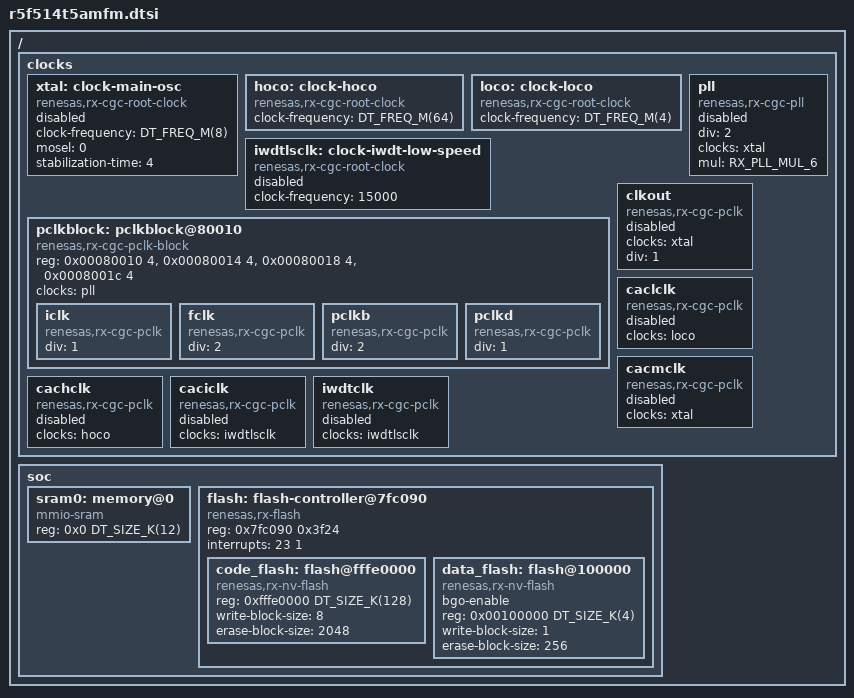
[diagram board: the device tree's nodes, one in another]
/*
 * Copyright (c) 2026 Renesas Electronics Corporation
 *
 * SPDX-License-Identifier: Apache-2.0
 */
#include <rx/renesas/rx14t-common.dtsi>
#include <freq.h>
#include <zephyr/dt-bindings/clock/rx_clock.h>

/ {
	clocks: clocks {
		#address-cells = <1>;
		#size-cells = <1>;

		xtal: clock-main-osc {
			compatible = "renesas,rx-cgc-root-clock";
			clock-frequency = <DT_FREQ_M(8)>;
			mosel = <0>;
			stabilization-time = <4>;
			#clock-cells = <0>;
			status = "disabled";
		};

		hoco: clock-hoco {
			compatible = "renesas,rx-cgc-root-clock";
			clock-frequency = <DT_FREQ_M(64)>;
			#clock-cells = <0>;
			status = "okay";
		};

		loco: clock-loco {
			compatible = "renesas,rx-cgc-root-clock";
			clock-frequency = <DT_FREQ_M(4)>;
			#clock-cells = <0>;
			status = "okay";
		};

		iwdtlsclk: clock-iwdt-low-speed {
			compatible = "renesas,rx-cgc-root-clock";
			clock-frequency = <15000>;
			#clock-cells = <0>;
			status = "disabled";
		};

		pll: pll {
			compatible = "renesas,rx-cgc-pll";
			#clock-cells = <0>;
			div = <2>;
			clocks = <&xtal>;
			mul = <RX_PLL_MUL_6>;
			status = "disabled";
		};

		pclkblock: pclkblock@80010 {
			compatible = "renesas,rx-cgc-pclk-block";
			reg = <0x00080010 4>, <0x00080014 4>, <0x00080018 4>,
			      <0x0008001c 4>;
			reg-names = "MSTPA", "MSTPB", "MSTPC", "MSTPD";
			#clock-cells = <0>;
			clocks = <&pll>;
			status = "okay";

			iclk: iclk {
				compatible = "renesas,rx-cgc-pclk";
				div = <1>;
				#clock-cells = <2>;
				status = "okay";
			};

			fclk: fclk {
				compatible = "renesas,rx-cgc-pclk";
				div = <2>;
				#clock-cells = <2>;
				status = "okay";
			};

			pclkb: pclkb {
				compatible = "renesas,rx-cgc-pclk";
				div = <2>;
				#clock-cells = <2>;
				status = "okay";
			};

			pclkd: pclkd {
				compatible = "renesas,rx-cgc-pclk";
				div = <1>;
				#clock-cells = <2>;
				status = "okay";
			};
		};

		clkout: clkout {
			compatible = "renesas,rx-cgc-pclk";
			clocks = <&xtal>;
			div = <1>;
			#clock-cells = <2>;
			status = "disabled";
		};

		caclclk: caclclk {
			compatible = "renesas,rx-cgc-pclk";
			clocks = <&loco>;
			#clock-cells = <2>;
			status = "disabled";
		};

		cacmclk: cacmclk {
			compatible = "renesas,rx-cgc-pclk";
			clocks = <&xtal>;
			#clock-cells = <2>;
			status = "disabled";
		};

		cachclk: cachclk {
			compatible = "renesas,rx-cgc-pclk";
			clocks = <&hoco>;
			#clock-cells = <2>;
			status = "disabled";
		};

		caciclk: caciclk {
			compatible = "renesas,rx-cgc-pclk";
			clocks = <&iwdtlsclk>;
			#clock-cells = <2>;
			status = "disabled";
		};

		iwdtclk: iwdtclk {
			compatible = "renesas,rx-cgc-pclk";
			clocks = <&iwdtlsclk>;
			#clock-cells = <2>;
			status = "disabled";
		};
	};

	soc {
		sram0: memory@0 {
			device_type = "memory";
			compatible = "mmio-sram";
			reg = <0x0 DT_SIZE_K(12)>;
		};

		flash: flash-controller@7fc090 {
			#address-cells = <1>;
			#size-cells = <1>;
			compatible = "renesas,rx-flash";
			reg = <0x7fc090 0x3f24>;
			interrupts = <23 1>;
			interrupt-names = "frdyi";

			code_flash: flash@fffe0000 {
				#address-cells = <1>;
				#size-cells = <1>;
				compatible = "renesas,rx-nv-flash";
				reg = <0xfffe0000 DT_SIZE_K(128)>;
				ranges = <0x0 0xfffe0000 DT_SIZE_K(128)>;
				write-block-size = <8>;
				erase-block-size = <2048>;
			};

			data_flash: flash@100000 {
				#address-cells = <1>;
				#size-cells = <1>;
				compatible = "renesas,rx-nv-flash";
				bgo-enable;
				reg = <0x00100000 DT_SIZE_K(4)>;
				ranges = <0x0 0x00100000 DT_SIZE_K(4)>;
				write-block-size = <1>;
				erase-block-size = <256>;
			};
		};
	};
};
